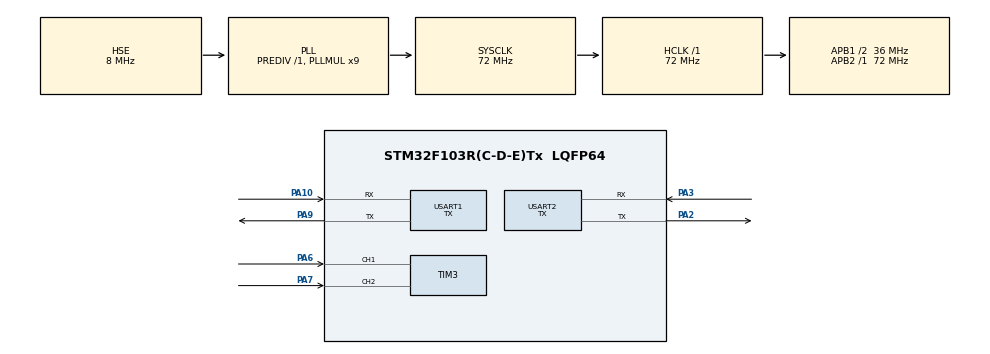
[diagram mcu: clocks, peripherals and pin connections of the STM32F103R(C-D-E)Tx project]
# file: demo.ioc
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Mcu.Family=STM32F1
Mcu.Name=STM32F103R(C-D-E)Tx
Mcu.Package=LQFP64
NVIC.PriorityGroup=NVIC_PRIORITYGROUP_4
NVIC.USART1_IRQn=true\:0\:0\:false\:false\:true\:true\:true\:true
PA10.Mode=Asynchronous
PA10.Signal=USART1_RX
PA13.Mode=Serial_Wire
PA13.Signal=SYS_JTMS-SWDIO
PA14.Mode=Serial_Wire
PA14.Signal=SYS_JTCK-SWCLK
PA2.Mode=Asynchronous
PA2.Signal=USART2_TX
PA3.Mode=Asynchronous
PA3.Signal=USART2_RX
PA6.Signal=S_TIM3_CH1
PA7.Signal=S_TIM3_CH2
PA9.Mode=Asynchronous
PA9.Signal=USART1_TX
PD0-OSC_IN.Mode=HSE-External-Oscillator
PD0-OSC_IN.Signal=RCC_OSC_IN
PD1-OSC_OUT.Mode=HSE-External-Oscillator
PD1-OSC_OUT.Signal=RCC_OSC_OUT
ProjectManager.HeapSize=0x200
ProjectManager.StackSize=0x400
ProjectManager.TargetToolchain=MDK-ARM V5
RCC.AHBFreq_Value=72000000
RCC.APB1CLKDivider=RCC_HCLK_DIV2
RCC.APB1Freq_Value=36000000
RCC.APB1TimFreq_Value=72000000
RCC.APB2Freq_Value=72000000
RCC.APB2TimFreq_Value=72000000
RCC.HCLKFreq_Value=72000000
RCC.PLLMUL=RCC_PLL_MUL9
RCC.PLLSourceVirtual=RCC_PLLSOURCE_HSE
RCC.SYSCLKFreq_VALUE=72000000
RCC.SYSCLKSource=RCC_SYSCLKSOURCE_PLLCLK
RCC.USBFreq_Value=72000000
SH.S_TIM3_CH1.0=TIM3_CH1,Encoder_Interface
SH.S_TIM3_CH2.0=TIM3_CH2,Encoder_Interface
TIM3.ClockDivision=TIM_CLOCKDIVISION_DIV1
TIM3.IC1Filter=6
TIM3.IC1Polarity=TIM_ICPOLARITY_FALLING
TIM3.IC2Filter=6
TIM3.IC2Polarity=TIM_ICPOLARITY_FALLING
USART1.Mode=MODE_TX
USART1.VirtualMode=VM_ASYNC
USART2.Mode=MODE_TX
USART2.VirtualMode=VM_ASYNC
board=custom

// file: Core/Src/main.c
/* USER CODE BEGIN Header */
/**
 ******************************************************************************
 * @file           : main.c
 * @brief          : Main program body
 ******************************************************************************
 * @attention
 *
 * <h2><center>&copy; Copyright (c) 2022 STMicroelectronics.
 * All rights reserved.</center></h2>
 *
 * This software component is licensed by ST under BSD 3-Clause license,
 * the "License"; You may not use this file except in compliance with the
 * License. You may obtain a copy of the License at:
 *                        opensource.org/licenses/BSD-3-Clause
 *
 ******************************************************************************
 */
/* USER CODE END Header */
#include "main.h"
#include "gpio.h"
#include "tim.h"
#include "usart.h"

/* USER CODE BEGIN PD */
#define ENCODER_TIM htim3
#define ENCODER_DIFF 0x7FFF
/* USER CODE END PD */

void SystemClock_Config(void);

int main(void) {

    /* MCU Configuration--------------------------------------------------------*/

    /* Reset of all peripherals, Initializes the Flash interface and the Systick. */
    HAL_Init();

    /* Configure the system clock */
    SystemClock_Config();

    /* Initialize all configured peripherals */
    MX_GPIO_Init();
    MX_USART1_UART_Init();
    MX_USART2_UART_Init();
    MX_TIM3_Init();
    /* USER CODE BEGIN 2 */
    // HAL_TIM_Encoder_Start(&htim3);
    /* USER CODE END 2 */

    /* Infinite loop */
    /* USER CODE BEGIN WHILE */
    __HAL_TIM_SetCounter(&ENCODER_TIM, ENCODER_DIFF);
    HAL_TIM_Encoder_Start(&ENCODER_TIM, TIM_CHANNEL_ALL);
    while (1) {
        int8_t count = __HAL_TIM_GetCounter(&ENCODER_TIM) - ENCODER_DIFF;
        if (count != 0) {  // 正转值为正 反转值为负
            __HAL_TIM_SetCounter(&ENCODER_TIM, ENCODER_DIFF);
            printf("%d\r\n", count);
        }
        /* USER CODE END WHILE */

    }
}

void SystemClock_Config(void) {
    RCC_OscInitTypeDef RCC_OscInitStruct = {0};
    RCC_ClkInitTypeDef RCC_ClkInitStruct = {0};

    /** Initializes the RCC Oscillators according to the specified parameters
     * in the RCC_OscInitTypeDef structure.
     */
    RCC_OscInitStruct.OscillatorType = RCC_OSCILLATORTYPE_HSE;
    RCC_OscInitStruct.HSEState       = RCC_HSE_ON;
    RCC_OscInitStruct.HSEPredivValue = RCC_HSE_PREDIV_DIV1;
    RCC_OscInitStruct.HSIState       = RCC_HSI_ON;
    RCC_OscInitStruct.PLL.PLLState   = RCC_PLL_ON;
    RCC_OscInitStruct.PLL.PLLSource  = RCC_PLLSOURCE_HSE;
    RCC_OscInitStruct.PLL.PLLMUL     = RCC_PLL_MUL9;
    if (HAL_RCC_OscConfig(&RCC_OscInitStruct) != HAL_OK) {
        Error_Handler();
    }

    /** Initializes the CPU, AHB and APB buses clocks
     */
    RCC_ClkInitStruct.ClockType      = RCC_CLOCKTYPE_HCLK | RCC_CLOCKTYPE_SYSCLK | RCC_CLOCKTYPE_PCLK1 | RCC_CLOCKTYPE_PCLK2;
    RCC_ClkInitStruct.SYSCLKSource   = RCC_SYSCLKSOURCE_PLLCLK;
    RCC_ClkInitStruct.AHBCLKDivider  = RCC_SYSCLK_DIV1;
    RCC_ClkInitStruct.APB1CLKDivider = RCC_HCLK_DIV2;
    RCC_ClkInitStruct.APB2CLKDivider = RCC_HCLK_DIV1;

    if (HAL_RCC_ClockConfig(&RCC_ClkInitStruct, FLASH_LATENCY_2) != HAL_OK) {
        Error_Handler();
    }
}

void Error_Handler(void) {
}
